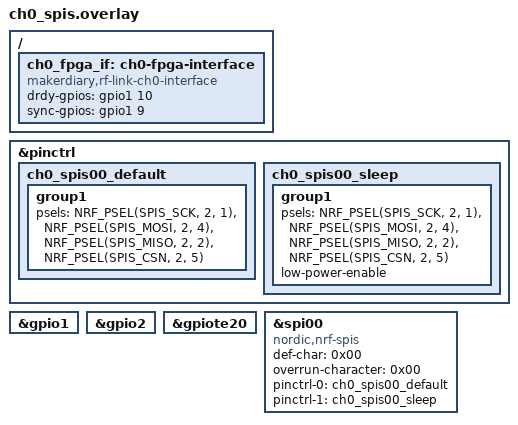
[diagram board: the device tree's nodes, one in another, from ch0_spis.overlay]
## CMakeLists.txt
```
#
# Copyright (c) 2018 Nordic Semiconductor
# Copyright (c) 2016-2025 Makerdiary <https://makerdiary.com>
#
# SPDX-License-Identifier: LicenseRef-Nordic-5-Clause
#
cmake_minimum_required(VERSION 3.20.0)

set(USER_CACHE_DIR "${CMAKE_BINARY_DIR}/zephyr_cache" CACHE PATH "Local build cache")
find_package(Zephyr REQUIRED HINTS $ENV{ZEPHYR_BASE})
project(rf_link_rx)

# NORDIC SDK APP START
target_sources(app PRIVATE
  src/main.c
  src/debug_uart.c
  src/radio_link.c
  src/rx_reorder.c
  src/rx_sample_stream.c
  src/timebase.c
)

target_sources_ifdef(CONFIG_RF_LINK_FUTURE_MODE app PRIVATE
  src/frame_queue.c
  src/sync_manager.c
  src/fpga_transport.c
  src/fpga_spi_transport.c
  src/link_control.c
)

target_sources_ifdef(CONFIG_RF_LINK_FPGA_SPIS app PRIVATE
  src/fpga_spis_backend.c
)

target_include_directories(app PRIVATE
  src
  ${CMAKE_CURRENT_SOURCE_DIR}/../rf_link_common
)

# NORDIC SDK APP END
```

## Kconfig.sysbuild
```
source "share/sysbuild/Kconfig"
```

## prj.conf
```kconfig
CONFIG_NCS_APPLICATION_BOOT_BANNER_STRING="RF Link RX"

CONFIG_SERIAL=y
CONFIG_CONSOLE=y
CONFIG_UART_CONSOLE=n

CONFIG_ESB=y
CONFIG_ESB_MAX_PAYLOAD_LENGTH=224
CONFIG_ESB_TX_FIFO_SIZE=16
CONFIG_ESB_RX_FIFO_SIZE=16
CONFIG_CLOCK_CONTROL=y
CONFIG_NRFX_DPPI10=y
CONFIG_ASSERT=y

CONFIG_MAIN_STACK_SIZE=4096
```

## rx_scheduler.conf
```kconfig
CONFIG_MAIN_THREAD_PRIORITY=1
CONFIG_RF_LINK_FPGA_SPIS_THREAD_PRIORITY=0
```

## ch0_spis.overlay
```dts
#include <zephyr/dt-bindings/gpio/gpio.h>
#include <zephyr/dt-bindings/pinctrl/nrf-pinctrl.h>

/ {
	ch0_fpga_if: ch0-fpga-interface {
		compatible = "makerdiary,rf-link-ch0-interface";
		drdy-gpios = <&gpio1 10 GPIO_ACTIVE_HIGH>;
		sync-gpios = <&gpio1 9 GPIO_ACTIVE_HIGH>;
	};
};

&pinctrl {
	ch0_spis00_default: ch0_spis00_default {
		group1 {
			psels = <NRF_PSEL(SPIS_SCK, 2, 1)>,
				<NRF_PSEL(SPIS_MOSI, 2, 4)>,
				<NRF_PSEL(SPIS_MISO, 2, 2)>,
				<NRF_PSEL(SPIS_CSN, 2, 5)>;
		};
	};

	ch0_spis00_sleep: ch0_spis00_sleep {
		group1 {
			psels = <NRF_PSEL(SPIS_SCK, 2, 1)>,
				<NRF_PSEL(SPIS_MOSI, 2, 4)>,
				<NRF_PSEL(SPIS_MISO, 2, 2)>,
				<NRF_PSEL(SPIS_CSN, 2, 5)>;
			low-power-enable;
		};
	};
};

&gpio1 {
	status = "okay";
};

&gpio2 {
	status = "okay";
};

&gpiote20 {
	status = "okay";
};

&spi00 {
	compatible = "nordic,nrf-spis";
	status = "okay";
	def-char = <0x00>;
	overrun-character = <0x00>;
	pinctrl-0 = <&ch0_spis00_default>;
	pinctrl-1 = <&ch0_spis00_sleep>;
	pinctrl-names = "default", "sleep";
	/delete-property/ rx-delay-supported;
	/delete-property/ rx-delay;
};
```

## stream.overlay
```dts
/*
 * Stream-only UART rate selection. Pin routing remains defined by the board
 * and the application's normal board overlay.
 */
&uart30 {
	current-speed = <1000000>;
};
```

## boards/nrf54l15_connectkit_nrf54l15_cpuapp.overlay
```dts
/ {
	chosen {
		zephyr,console = &uart30;
		zephyr,shell-uart = &uart30;
	};
};

&uart30 {
	status = "okay";
	current-speed = <115200>;
	/delete-property/ hw-flow-control;
};
```

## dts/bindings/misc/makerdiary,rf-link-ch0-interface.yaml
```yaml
description: CH0 FPGA sideband GPIOs for the RF Link receiver

compatible: "makerdiary,rf-link-ch0-interface"

properties:
  drdy-gpios:
    type: phandle-array
    required: true
    description: Active-high level indicating a pending PEEK record

  sync-gpios:
    type: phandle-array
    required: true
    description: Active-high external synchronization input
```

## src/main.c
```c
#include <stdint.h>
#include <string.h>
#include <zephyr/app_version.h>
#include <zephyr/kernel.h>

#include "debug_uart.h"
#include "rf_link_proto.h"
#include "radio_link.h"
#include "rx_reorder.h"
#include "rx_sample_stream.h"
#include "timebase.h"

#if defined(CONFIG_RF_LINK_FUTURE_MODE)
#include "fpga_transport.h"
#include "fpga_spis_backend.h"
#include "frame_queue.h"
#include "link_control.h"
#include "sync_manager.h"
#endif

static void print_boot_line(void)
{
	debug_uart_puts("\r\nrf_link_rx started");
	debug_uart_crlf();
	debug_uart_puts("mode=ESB_PRX,phy=");
	debug_uart_puts(radio_link_phy_label());
	debug_uart_puts(",ack=");
	debug_uart_puts(RF_LINK_NOACK_STREAM ? "noack" : "ack");
	debug_uart_puts(",channel=");
	debug_uart_u32(RF_LINK_CHANNEL);
	debug_uart_puts(",pipe=");
	debug_uart_u32(RF_LINK_PIPE);
	debug_uart_puts(",prefix=0x54,fw=");
	debug_uart_puts(STRINGIFY(APP_BUILD_VERSION));
	debug_uart_puts(",samples_per_frame=");
	debug_uart_u32(RF_LINK_FRAME_SAMPLE_COUNT);
#if defined(CONFIG_RF_LINK_FUTURE_MODE)
	debug_uart_puts(",v2_preview=1,node_id=");
	debug_uart_u32(CONFIG_RF_LINK_NODE_ID);
#endif
	debug_uart_crlf();
}

#if !defined(CONFIG_RF_LINK_FUTURE_MODE)
static void print_stats(uint32_t last_bytes, int64_t last_ms)
{
	struct radio_link_stats radio_stats;
	struct rx_reorder_stats rx_stats;
	uint32_t delta_bytes;
	uint32_t bps = 0;
	int64_t now = k_uptime_get();
	int64_t delta_ms = now - last_ms;

	radio_link_stats_get(&radio_stats);
	rx_reorder_stats_get(&rx_stats);

	delta_bytes = rx_stats.bytes - last_bytes;
	if (delta_ms > 0) {
		bps = (uint32_t)(((uint64_t)delta_bytes * 8000ull) / (uint64_t)delta_ms);
	}

	debug_uart_puts("RX stat frames=");
	debug_uart_u32(rx_stats.frames);
	debug_uart_puts(" samples=");
	debug_uart_u32(rx_stats.samples);
	debug_uart_puts(" bps=");
	debug_uart_u32(bps);
	debug_uart_puts(" lost=");
	debug_uart_u32(rx_stats.lost_frames);
	debug_uart_puts(" dup=");
	debug_uart_u32(rx_stats.duplicates);
	debug_uart_puts(" late=");
	debug_uart_u32(rx_stats.late_frames);
	debug_uart_puts(" bad=");
	debug_uart_u32(rx_stats.bad_magic + rx_stats.bad_size +
		       rx_stats.bad_sample_count);
	debug_uart_puts(" rf_evt=");
	debug_uart_u32(radio_stats.rx_events);
	debug_uart_puts(" rf_frames=");
	debug_uart_u32(radio_stats.rx_frames);
	debug_uart_puts(" rf_read_err=");
	debug_uart_u32(radio_stats.rx_read_errors);
	debug_uart_puts(" rf_q_ovf=");
	debug_uart_u32(radio_stats.rx_queue_overflow);
	debug_uart_puts(" rf_q_hwm=");
	debug_uart_u32(radio_stats.rx_queue_high_water);
	debug_uart_puts(" seq=");
	debug_uart_u32(rx_stats.last_seq);
	debug_uart_puts(" first=");
	debug_uart_i32(rx_stats.last_first_sample);
	debug_uart_puts(" last=");
	debug_uart_i32(rx_stats.last_last_sample);
	debug_uart_crlf();
}
#endif

#if defined(CONFIG_RF_LINK_FUTURE_MODE)
static void print_future_stats(void)
{
	struct frame_queue_stats queue_stats;
	struct link_control_status control_stats;
	struct radio_link_stats radio_stats;
	struct rx_reorder_stats reorder_stats;
	struct sync_status sync_stats;
	struct transport_stats transport_stats;

	radio_link_stats_get(&radio_stats);
	rx_reorder_stats_get(&reorder_stats);
	frame_queue_stats_get(&queue_stats);
	sync_manager_get_status(&sync_stats);
	memset(&transport_stats, 0, sizeof(transport_stats));
	if (IS_ENABLED(CONFIG_RF_LINK_FPGA_TRANSPORT)) {
		fpga_transport_get_stats(&transport_stats);
	}
	link_control_get_status(&control_stats);

	debug_uart_puts("RADIO events=");
	debug_uart_u32(radio_stats.rx_events);
	debug_uart_puts(" frames=");
	debug_uart_u32(radio_stats.rx_frames);
	debug_uart_puts(" read_errors=");
	debug_uart_u32(radio_stats.rx_read_errors);
	debug_uart_puts(" queue_overflow=");
	debug_uart_u32(radio_stats.rx_queue_overflow);
	debug_uart_puts(" queue_high_water=");
	debug_uart_u32(radio_stats.rx_queue_high_water);
	debug_uart_crlf();

	debug_uart_puts("REORDER extended_frame_seq=");
	debug_uart_u32(reorder_stats.extended_frame_seq);
	debug_uart_puts(" rf_lost_frames=");
	debug_uart_u32(reorder_stats.lost_frames);
	debug_uart_puts(" rf_lost_samples=");
	debug_uart_u32(reorder_stats.lost_samples);
	debug_uart_puts(" rf_duplicates=");
	debug_uart_u32(reorder_stats.duplicates);
	debug_uart_puts(" rf_late_frames=");
	debug_uart_u32(reorder_stats.late_frames);
	debug_uart_puts(" index_estimated=");
	debug_uart_u32(reorder_stats.index_estimated);
	debug_uart_puts(" bad_magic=");
	debug_uart_u32(reorder_stats.bad_magic);
	debug_uart_puts(" bad_size=");
	debug_uart_u32(reorder_stats.bad_size);
	debug_uart_puts(" bad_sample_count=");
	debug_uart_u32(reorder_stats.bad_sample_count);
	debug_uart_crlf();

	debug_uart_puts("SYNC state=");
	debug_uart_u32(sync_stats.state);
	debug_uart_puts(" sync_capture_count=");
	debug_uart_u32(sync_stats.sync_capture_count);
	debug_uart_puts(" sync_timeout=");
	debug_uart_u32(sync_stats.sync_timeout);
	debug_uart_puts(" sync_epoch=");
	debug_uart_u32(sync_stats.sync_epoch);
	debug_uart_puts(" sync_locked=");
	debug_uart_u32(sync_stats.sync_locked ? 1u : 0u);
	debug_uart_puts(" resync_count=");
	debug_uart_u32(sync_stats.resync_count);
	debug_uart_crlf();

	debug_uart_puts("QUEUE push_total=");
	debug_uart_u32(queue_stats.push_total);
	debug_uart_puts(" pop_total=");
	debug_uart_u32(queue_stats.pop_total);
	debug_uart_puts(" overflow=");
	debug_uart_u32(queue_stats.overflow);
	debug_uart_puts(" high_water=");
	debug_uart_u32(queue_stats.high_water);
	debug_uart_puts(" level=");
	debug_uart_u32(frame_queue_level());
	debug_uart_crlf();

	debug_uart_puts("SPI_TRANSPORT records=");
	debug_uart_u32(transport_stats.records);
	debug_uart_puts(" crc_errors=");
	debug_uart_u32(transport_stats.crc_errors);
	debug_uart_puts(" invalid_cmd=");
	debug_uart_u32(transport_stats.invalid_cmd);
	debug_uart_puts(" duplicate_commit=");
	debug_uart_u32(transport_stats.duplicate_commit);
	debug_uart_puts(" submit_errors=");
	debug_uart_u32(transport_stats.submit_errors);
	debug_uart_puts(" stall_ms=");
	debug_uart_u32(transport_stats.stall_ms);
	debug_uart_puts(" req_xfer=");
	debug_uart_u32(transport_stats.request_transactions);
	debug_uart_puts(" rsp_xfer=");
	debug_uart_u32(transport_stats.response_transactions);
	debug_uart_puts(" spi_errors=");
	debug_uart_u32(transport_stats.spi_errors);
	debug_uart_puts(" parser_errors=");
	debug_uart_u32(transport_stats.parser_errors);
	debug_uart_puts(" short_xfer=");
	debug_uart_u32(transport_stats.short_transfers);
	debug_uart_crlf();

#if defined(CONFIG_RF_LINK_FPGA_SPIS)
    struct fpga_spis_backend_stats physical;
    fpga_spis_backend_get_stats(&physical);
    debug_uart_puts("SPI_PHYSICAL req_len_err=");
    debug_uart_u32(physical.request_length_errors);
    debug_uart_puts(" rsp_len_err=");
    debug_uart_u32(physical.response_length_errors);
    debug_uart_puts(" recovery_discard=");
    debug_uart_u32(physical.recovery_discards);
    debug_uart_puts(" last_bad_req=");
    debug_uart_u32(physical.last_bad_request_length);
    debug_uart_puts(" last_bad_rsp=");
    debug_uart_u32(physical.last_bad_response_length);
    debug_uart_crlf();
#endif

	debug_uart_puts("CONTROL armed=");
	debug_uart_u32(control_stats.arm_commands);
	debug_uart_puts(" started=");
	debug_uart_u32(control_stats.start_commands);
	debug_uart_puts(" stopped=");
	debug_uart_u32(control_stats.stop_commands);
	debug_uart_puts(" reset=");
	debug_uart_u32(control_stats.reset_commands);
	debug_uart_puts(" invalid=");
	debug_uart_u32(control_stats.invalid_commands);
	debug_uart_crlf();
}

static int future_pipeline_init(void)
{
	int ret;

	frame_queue_init();
	link_control_init();
	ret = sync_manager_init();
	if (ret != 0) {
		return ret;
	}

	if (IS_ENABLED(CONFIG_RF_LINK_FPGA_TRANSPORT)) {
		return fpga_transport_init();
	}

	return 0;
}

static void future_process_record(struct rx_frame_record *record)
{
	struct rx_reorder_stats reorder_stats;
	int ret;

	if ((record->status_flags & RX_FRAME_STATUS_GAP_BEFORE) != 0u) {
		rx_reorder_stats_get(&reorder_stats);
		sync_manager_on_sequence_gap(
			reorder_stats.last_missing.frame_count);
	}

	sync_manager_on_frame(record);
	if (!link_control_streaming()) {
		return;
	}

	ret = frame_queue_push(record);
	if (ret != 0) {
		sync_manager_on_queue_overflow();
		return;
	}

	if (IS_ENABLED(CONFIG_RF_LINK_FPGA_TRANSPORT)) {
		(void)fpga_transport_service();
	} else {
		(void)frame_queue_commit(record->extended_frame_seq);
	}
}
#endif

int main(void)
{
#if !defined(CONFIG_RF_LINK_FUTURE_MODE)
	struct rx_reorder_stats rx_stats;
	uint32_t last_bytes = 0;
#endif
	struct radio_link_rx_packet packet;
	struct rx_frame_record record;
	int64_t last_ms;
	bool stream_mode = false;
	int ret;

	(void)debug_uart_init();
	print_boot_line();
	ret = timebase_init();
	if (ret != 0) {
		debug_uart_puts("timebase init failed err=");
		debug_uart_i32(ret);
		debug_uart_crlf();
		return ret;
	}

#if defined(CONFIG_RF_LINK_RX_SAMPLE_STREAM)
	if (debug_uart_ready()) {
		debug_uart_puts("rx_sample_stream enabled, switch host to baud=");
		debug_uart_u32(CONFIG_RF_LINK_RX_SAMPLE_STREAM_UART_BAUD);
		debug_uart_crlf();
	}
#endif

	if (IS_ENABLED(CONFIG_RF_LINK_RX_SAMPLE_STREAM)) {
		ret = rx_sample_stream_init();
		if (ret != 0) {
			if (debug_uart_ready()) {
				debug_uart_puts("rx_sample_stream init failed err=");
				debug_uart_i32(ret);
				debug_uart_crlf();
				debug_uart_puts("fall back to RX stat mode");
				debug_uart_crlf();
			}
		} else {
			stream_mode = true;
		}
	}

	rx_reorder_init();

#if defined(CONFIG_RF_LINK_FUTURE_MODE)
	ret = future_pipeline_init();
	if (ret != 0) {
		debug_uart_puts("future pipeline init failed err=");
		debug_uart_i32(ret);
		debug_uart_crlf();
		if (IS_ENABLED(CONFIG_RF_LINK_FPGA_SPIS)) {
			debug_uart_puts("CH0 SPIS backend init failed; check reviewed overlay and wiring");
			debug_uart_crlf();
		}
		return ret;
	}
#endif

	ret = radio_link_init();
	if (ret != 0) {
		if (!stream_mode) {
			debug_uart_puts("radio init failed err=");
			debug_uart_i32(ret);
			debug_uart_crlf();
		}
		return ret;
	}

	if (!stream_mode) {
		debug_uart_puts("radio ready, waiting packets");
		debug_uart_crlf();
	}

	last_ms = k_uptime_get();
	while (1) {
		ret = radio_link_receive(&packet, K_MSEC(20));
		if (ret == 0) {
			ret = rx_reorder_process_packet(&packet.frame, packet.length,
						 packet.rx_tick, &record);
			if (ret == 0) {
#if defined(CONFIG_RF_LINK_FUTURE_MODE)
				future_process_record(&record);
#else
				rx_sample_stream_submit_frame(&record.frame);
#endif
			}
		}

#if defined(CONFIG_RF_LINK_FUTURE_MODE)
		sync_manager_poll(timebase_now_ticks());
		if (IS_ENABLED(CONFIG_RF_LINK_FPGA_TRANSPORT)) {
			(void)fpga_transport_service();
		}
#endif

		if (!stream_mode &&
		    (k_uptime_get() - last_ms) >= RF_LINK_STATUS_PERIOD_MS) {
#if defined(CONFIG_RF_LINK_FUTURE_MODE)
			print_future_stats();
#else
			print_stats(last_bytes, last_ms);
			rx_reorder_stats_get(&rx_stats);
			last_bytes = rx_stats.bytes;
#endif
			last_ms = k_uptime_get();
		}
	}
}
```

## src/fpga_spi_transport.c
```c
#include "fpga_spi_transport.h"

#include <errno.h>
#include <stddef.h>
#include <string.h>
#include <zephyr/spinlock.h>
#include <zephyr/sys/crc.h>

static struct k_spinlock spi_lock;
static struct fpga_record pending_record;
static struct fpga_spi_transport_stats spi_stats;
static fpga_spi_release_cb_t release_callback;
static fpga_spi_control_cb_t control_callback;
static void *callback_context;
static uint32_t pending_extended_frame_seq;
static uint32_t last_committed_transport_seq;
static bool have_last_commit;
static bool have_pending_record;
static bool commit_in_progress;
static bool abort_requested;

static uint16_t record_header_crc(const struct fpga_record_header *header)
{
	return crc16(0x1021u, 0xffffu, (const uint8_t *)header,
		     offsetof(struct fpga_record_header, header_crc16));
}

static bool record_crc_valid(const struct fpga_record *record)
{
	return record != NULL &&
	       record->header.magic == FPGA_RECORD_MAGIC &&
	       record->header.version == FPGA_RECORD_VERSION &&
	       record->header.payload_len == RF_LINK_FRAME_WIRE_SIZE &&
	       record->header.header_crc16 == record_header_crc(&record->header) &&
	       record->payload_crc32 ==
		crc32_ieee((const uint8_t *)&record->frame, sizeof(record->frame));
}

int fpga_spi_transport_init(fpga_spi_release_cb_t release_cb,
			    fpga_spi_control_cb_t control_cb,
			    void *context)
{
	k_spinlock_key_t key;

	if (release_cb == NULL) {
		return -EINVAL;
	}

	key = k_spin_lock(&spi_lock);
	memset(&pending_record, 0, sizeof(pending_record));
	memset(&spi_stats, 0, sizeof(spi_stats));
	release_callback = release_cb;
	control_callback = control_cb;
	callback_context = context;
	pending_extended_frame_seq = 0u;
	last_committed_transport_seq = 0u;
	have_last_commit = false;
	have_pending_record = false;
	commit_in_progress = false;
	abort_requested = false;
	k_spin_unlock(&spi_lock, key);
	return 0;
}

int fpga_spi_transport_stage(const struct fpga_record *record,
			     uint32_t extended_frame_seq)
{
	k_spinlock_key_t key;

	if (!record_crc_valid(record)) {
		key = k_spin_lock(&spi_lock);
		spi_stats.crc_errors++;
		k_spin_unlock(&spi_lock, key);
		return -EBADMSG;
	}

	key = k_spin_lock(&spi_lock);
	if (have_pending_record) {
		k_spin_unlock(&spi_lock, key);
		return -EBUSY;
	}

	pending_record = *record;
	pending_extended_frame_seq = extended_frame_seq;
	have_pending_record = true;
	k_spin_unlock(&spi_lock, key);
	return 0;
}

static int commit_or_drop(uint32_t transport_seq, bool drop)
{
	uint32_t extended_frame_seq;
	int ret;
	k_spinlock_key_t key = k_spin_lock(&spi_lock);

	if (!have_pending_record) {
		if (have_last_commit && transport_seq == last_committed_transport_seq) {
			spi_stats.duplicate_commit++;
			k_spin_unlock(&spi_lock, key);
			return -EALREADY;
		}

		spi_stats.invalid_cmd++;
		k_spin_unlock(&spi_lock, key);
		return -ENODATA;
	}
	if (commit_in_progress) {
		k_spin_unlock(&spi_lock, key);
		return -EBUSY;
	}

	if (transport_seq != pending_record.header.transport_seq) {
		spi_stats.invalid_cmd++;
		k_spin_unlock(&spi_lock, key);
		return -ESTALE;
	}

	extended_frame_seq = pending_extended_frame_seq;
	commit_in_progress = true;
	k_spin_unlock(&spi_lock, key);
	ret = release_callback(extended_frame_seq, drop, callback_context);
	key = k_spin_lock(&spi_lock);
	commit_in_progress = false;
	if (abort_requested) {
		abort_requested = false;
		have_pending_record = false;
		k_spin_unlock(&spi_lock, key);
		return (ret == 0) ? -ECANCELED : ret;
	}
	if (ret != 0) {
		k_spin_unlock(&spi_lock, key);
		return ret;
	}

	last_committed_transport_seq = transport_seq;
	have_last_commit = true;
	have_pending_record = false;
	if (drop) {
		spi_stats.drop_total++;
	} else {
		spi_stats.commit_total++;
	}
	k_spin_unlock(&spi_lock, key);
	return 0;
}

int fpga_spi_transport_execute(const struct fpga_command *command,
			       struct fpga_response *response)
{
	int ret = 0;
	k_spinlock_key_t key;

	if (command == NULL || response == NULL) {
		return -EINVAL;
	}

	memset(response, 0, sizeof(*response));
	switch ((enum fpga_command_code)command->code) {
	case FPGA_CMD_GET_INFO:
	case FPGA_CMD_GET_STATUS:
		break;
	case FPGA_CMD_PEEK_RECORD:
	case FPGA_CMD_READ_RECORD:
		key = k_spin_lock(&spi_lock);
		if (!have_pending_record) {
			ret = -ENODATA;
		} else {
			response->record = pending_record;
			response->record_valid = true;
			response->transport_seq =
				pending_record.header.transport_seq;
			spi_stats.read_total++;
		}
		k_spin_unlock(&spi_lock, key);
		break;
	case FPGA_CMD_COMMIT_RECORD:
		ret = commit_or_drop(command->argument, false);
		break;
	case FPGA_CMD_DROP_RECORD:
		ret = commit_or_drop(command->argument, true);
		break;
	case FPGA_CMD_CLEAR_STATS:
		key = k_spin_lock(&spi_lock);
		memset(&spi_stats, 0, sizeof(spi_stats));
		k_spin_unlock(&spi_lock, key);
		if (control_callback != NULL) {
			ret = control_callback(FPGA_CMD_CLEAR_STATS, 0u,
					       callback_context);
		}
		break;
	case FPGA_CMD_ARM_SYNC:
	case FPGA_CMD_START_STREAM:
	case FPGA_CMD_STOP_STREAM:
	case FPGA_CMD_RESET_LINK:
		if (control_callback == NULL) {
			ret = -ENOTSUP;
		} else {
			ret = control_callback(
				(enum fpga_command_code)command->code,
				command->argument, callback_context);
		}
		break;
	default:
		key = k_spin_lock(&spi_lock);
		spi_stats.invalid_cmd++;
		k_spin_unlock(&spi_lock, key);
		ret = -ENOTSUP;
		break;
	}

	response->status = ret;
	return ret;
}

bool fpga_spi_transport_pending(void)
{
	k_spinlock_key_t key = k_spin_lock(&spi_lock);
	bool pending = have_pending_record;

	k_spin_unlock(&spi_lock, key);
	return pending;
}

uint32_t fpga_spi_transport_pending_seq(void)
{
	k_spinlock_key_t key = k_spin_lock(&spi_lock);
	uint32_t seq = have_pending_record ?
		pending_record.header.transport_seq : UINT32_MAX;

	k_spin_unlock(&spi_lock, key);
	return seq;
}

void fpga_spi_transport_abort_pending(void)
{
	k_spinlock_key_t key = k_spin_lock(&spi_lock);

	if (commit_in_progress) {
		abort_requested = true;
		k_spin_unlock(&spi_lock, key);
		return;
	}

	have_pending_record = false;
	pending_extended_frame_seq = 0u;
	commit_in_progress = false;
	abort_requested = false;
	k_spin_unlock(&spi_lock, key);
}

void fpga_spi_transport_stats_get(struct fpga_spi_transport_stats *stats)
{
	k_spinlock_key_t key;

	if (stats == NULL) {
		return;
	}

	key = k_spin_lock(&spi_lock);
	*stats = spi_stats;
	k_spin_unlock(&spi_lock, key);
}
```

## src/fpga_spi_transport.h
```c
#ifndef RF_LINK_FPGA_SPI_TRANSPORT_H_
#define RF_LINK_FPGA_SPI_TRANSPORT_H_

#include <stdbool.h>
#include <stdint.h>

#include "rf_link_future.h"

enum fpga_command_code {
	FPGA_CMD_GET_INFO = 1,
	FPGA_CMD_GET_STATUS,
	FPGA_CMD_PEEK_RECORD,
	FPGA_CMD_READ_RECORD,
	FPGA_CMD_COMMIT_RECORD,
	FPGA_CMD_DROP_RECORD,
	FPGA_CMD_CLEAR_STATS,
	FPGA_CMD_ARM_SYNC,
	FPGA_CMD_START_STREAM,
	FPGA_CMD_STOP_STREAM,
	FPGA_CMD_RESET_LINK,
};

#define FPGA_INFO_MAGIC                 0x3149464eu
#define FPGA_STATUS_MAGIC               0x3153464eu
#define FPGA_SPI_CONTRACT_VERSION       1u
#define FPGA_SPI_BIT_ORDER_MSB_FIRST    0u
#define FPGA_CAP_PEEK_COMMIT            BIT(0)
#define FPGA_CAP_LEVEL_DRDY             BIT(1)
#define FPGA_CAP_HW_SYNC_CAPTURE        BIT(2)

struct fpga_info_payload {
	uint32_t magic;
	uint16_t contract_version;
	uint16_t capabilities;
	uint16_t request_size;
	uint16_t response_size;
	uint16_t record_size;
	uint8_t spi_mode;
	uint8_t bit_order;
	uint32_t max_sclk_hz;
	uint32_t initial_sclk_hz;
	uint32_t min_request_response_gap_us;
} __packed;

struct fpga_status_payload {
	uint32_t magic;
	uint16_t contract_version;
	uint16_t sync_state;
	uint32_t queue_level;
	uint32_t queue_high_water;
	uint32_t sync_epoch;
	uint64_t sync_tick;
	uint32_t pending_transport_seq;
	uint32_t crc_errors;
	uint32_t invalid_cmd;
	uint32_t duplicate_commit;
	uint32_t spi_errors;
	uint32_t parser_errors;
	uint32_t short_transfers;
} __packed;

struct fpga_command {
	uint8_t code;
	uint8_t reserved[3];
	uint32_t argument;
} __packed;

struct fpga_response {
	int32_t status;
	uint32_t transport_seq;
	uint8_t record_valid;
	uint8_t reserved[3];
	union {
		struct fpga_record record;
		uint8_t payload[sizeof(struct fpga_record)];
	};
} __packed;

/*
 * The command engine's current wire image is little-endian on nRF54L15.
 * A physical SPIS backend may add turnaround/dummy clocks, but it must not
 * silently change these request/response payload sizes.
 */
#define FPGA_SPI_REQUEST_SIZE  8u
#define FPGA_SPI_RESPONSE_SIZE 260u

BUILD_ASSERT(sizeof(struct fpga_command) == FPGA_SPI_REQUEST_SIZE,
	     "fpga_command wire size changed");
BUILD_ASSERT(sizeof(struct fpga_response) == FPGA_SPI_RESPONSE_SIZE,
	     "fpga_response wire size changed");
BUILD_ASSERT(sizeof(struct fpga_info_payload) == 28u,
	     "GET_INFO wire payload size changed");
BUILD_ASSERT(sizeof(struct fpga_status_payload) == 56u,
	     "GET_STATUS wire payload size changed");
BUILD_ASSERT(sizeof(struct fpga_status_payload) <= sizeof(struct fpga_record),
	     "status payload is too large for the response envelope");

struct fpga_spi_transport_stats {
	uint32_t crc_errors;
	uint32_t invalid_cmd;
	uint32_t duplicate_commit;
	uint32_t read_total;
	uint32_t commit_total;
	uint32_t drop_total;
};

typedef int (*fpga_spi_release_cb_t)(uint32_t extended_frame_seq,
				      bool drop, void *context);
typedef int (*fpga_spi_control_cb_t)(enum fpga_command_code command,
				      uint32_t argument, void *context);

int fpga_spi_transport_init(fpga_spi_release_cb_t release_cb,
			    fpga_spi_control_cb_t control_cb,
			    void *context);
int fpga_spi_transport_stage(const struct fpga_record *record,
			     uint32_t extended_frame_seq);
int fpga_spi_transport_execute(const struct fpga_command *command,
			       struct fpga_response *response);
bool fpga_spi_transport_pending(void);
uint32_t fpga_spi_transport_pending_seq(void);
void fpga_spi_transport_abort_pending(void);
void fpga_spi_transport_stats_get(struct fpga_spi_transport_stats *stats);

#endif /* RF_LINK_FPGA_SPI_TRANSPORT_H_ */
```

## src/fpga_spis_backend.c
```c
#include "fpga_spis_backend.h"

#include <errno.h>
#include <string.h>
#include <zephyr/device.h>
#include <zephyr/devicetree.h>
#include <zephyr/drivers/gpio.h>
#include <zephyr/drivers/spi.h>
#include <zephyr/kernel.h>
#include <zephyr/spinlock.h>
#include <zephyr/sys/util.h>

#include "fpga_spi_transport.h"
#include "fpga_transport.h"
#include "frame_queue.h"
#include "sync_manager.h"

#define CH0_SPIS_NODE DT_NODELABEL(spi00)
#define CH0_FPGA_IF_NODE DT_NODELABEL(ch0_fpga_if)

BUILD_ASSERT(DT_NODE_HAS_STATUS(CH0_SPIS_NODE, okay),
	     "CH0 overlay must enable spi00");
BUILD_ASSERT(DT_NODE_HAS_PROP(CH0_FPGA_IF_NODE, drdy_gpios),
	     "CH0 overlay must define drdy-gpios");

static const struct device *const spis = DEVICE_DT_GET(CH0_SPIS_NODE);
static const struct gpio_dt_spec drdy =
	GPIO_DT_SPEC_GET(CH0_FPGA_IF_NODE, drdy_gpios);
static const struct spi_config spis_config = {
	.frequency = 1000000u,
	.operation = SPI_OP_MODE_SLAVE | SPI_WORD_SET(8),
	.slave = 0u,
};

static uint8_t request_tx[FPGA_SPI_REQUEST_SIZE];
/* RX AMOUNT is capped by MAXCNT. A full recovery transaction must
 * remain distinguishable from an eight-byte command, even if the master
 * and slave have lost their A/B phase agreement. */
static uint8_t request_rx[FPGA_SPI_RESPONSE_SIZE];
static uint8_t response_rx[FPGA_SPI_RESPONSE_SIZE];
static struct fpga_response response_tx;
static struct k_thread spis_thread;
K_THREAD_STACK_DEFINE(spis_stack,
		      CONFIG_RF_LINK_FPGA_SPIS_THREAD_STACK_SIZE);
static struct k_spinlock backend_lock;
static struct fpga_spis_backend_stats backend_stats;
static bool backend_ready;

static void backend_stat_inc(uint32_t *counter)
{
	k_spinlock_key_t key = k_spin_lock(&backend_lock);

	(*counter)++;
	k_spin_unlock(&backend_lock, key);
}

static void update_drdy(void)
{
	(void)gpio_pin_set_dt(&drdy, fpga_spi_transport_pending() ? 1 : 0);
}

static void fill_info_response(struct fpga_response *response)
{
	struct fpga_info_payload info = {
		.magic = FPGA_INFO_MAGIC,
		.contract_version = FPGA_SPI_CONTRACT_VERSION,
		.capabilities = FPGA_CAP_PEEK_COMMIT | FPGA_CAP_LEVEL_DRDY |
				FPGA_CAP_HW_SYNC_CAPTURE,
		.request_size = FPGA_SPI_REQUEST_SIZE,
		.response_size = FPGA_SPI_RESPONSE_SIZE,
		.record_size = sizeof(struct fpga_record),
		.spi_mode = 0u,
		.bit_order = FPGA_SPI_BIT_ORDER_MSB_FIRST,
		.max_sclk_hz = 8000000u,
		.initial_sclk_hz = 1000000u,
		.min_request_response_gap_us = 1000u,
	};

	memcpy(response->payload, &info, sizeof(info));
}

static void fill_status_response(struct fpga_response *response)
{
	struct fpga_status_payload status = {0};
	struct fpga_spi_transport_stats command_stats;
	struct fpga_spis_backend_stats physical_stats;
	struct frame_queue_stats queue_stats;
	struct sync_status sync_status;

	fpga_spi_transport_stats_get(&command_stats);
	fpga_spis_backend_get_stats(&physical_stats);
	frame_queue_stats_get(&queue_stats);
	sync_manager_get_status(&sync_status);
	status.magic = FPGA_STATUS_MAGIC;
	status.contract_version = FPGA_SPI_CONTRACT_VERSION;
	status.sync_state = (uint16_t)sync_status.state;
	status.queue_level = frame_queue_level();
	status.queue_high_water = queue_stats.high_water;
	status.sync_epoch = sync_status.sync_epoch;
	status.sync_tick = sync_status.sync_tick;
	status.pending_transport_seq = fpga_spi_transport_pending_seq();
	status.crc_errors = command_stats.crc_errors;
	status.invalid_cmd = command_stats.invalid_cmd;
	status.duplicate_commit = command_stats.duplicate_commit;
	status.spi_errors = physical_stats.spi_errors;
	status.parser_errors = physical_stats.parser_errors;
	status.short_transfers = physical_stats.short_transfers;
	memcpy(response->payload, &status, sizeof(status));
}

static bool request_reserved_valid(const struct fpga_command *command)
{
	return command->reserved[0] == 0u && command->reserved[1] == 0u &&
	       command->reserved[2] == 0u;
}

static void spis_worker(void *arg1, void *arg2, void *arg3)
{
	const struct spi_buf request_tx_buf = {
		.buf = request_tx,
		.len = sizeof(request_tx),
	};
	const struct spi_buf request_rx_buf = {
		.buf = request_rx,
		.len = sizeof(request_rx),
	};
	const struct spi_buf_set request_tx_set = {
		.buffers = &request_tx_buf,
		.count = 1u,
	};
	const struct spi_buf_set request_rx_set = {
		.buffers = &request_rx_buf,
		.count = 1u,
	};
	const struct spi_buf response_tx_buf = {
		.buf = &response_tx,
		.len = sizeof(response_tx),
	};
	const struct spi_buf response_rx_buf = {
		.buf = response_rx,
		.len = sizeof(response_rx),
	};
	const struct spi_buf_set response_tx_set = {
		.buffers = &response_tx_buf,
		.count = 1u,
	};
	const struct spi_buf_set response_rx_set = {
		.buffers = &response_rx_buf,
		.count = 1u,
	};
	struct fpga_command command;
	int ret;

	ARG_UNUSED(arg1);
	ARG_UNUSED(arg2);
	ARG_UNUSED(arg3);
	while (true) {
		memset(request_rx, 0, sizeof(request_rx));
		ret = spi_transceive(spis, &spis_config, &request_tx_set,
				     &request_rx_set);
		if (ret < 0) {
			backend_stat_inc(&backend_stats.spi_errors);
			continue;
		}
		backend_stat_inc(&backend_stats.request_transactions);
		if (ret != FPGA_SPI_REQUEST_SIZE) {
			backend_stat_inc(&backend_stats.short_transfers);
            backend_stat_inc(&backend_stats.request_length_errors);
            if (ret == FPGA_SPI_RESPONSE_SIZE) {
                backend_stat_inc(&backend_stats.recovery_discards);
            }
            backend_stats.last_bad_request_length = ret;
			continue;
		}

		memcpy(&command, request_rx, sizeof(command));
		memset(&response_tx, 0, sizeof(response_tx));
		if (!request_reserved_valid(&command)) {
			backend_stat_inc(&backend_stats.parser_errors);
			response_tx.status = -EBADMSG;
		} else {
			ret = fpga_spi_transport_execute(&command, &response_tx);
			if ((command.code == FPGA_CMD_COMMIT_RECORD ||
			     command.code == FPGA_CMD_DROP_RECORD) && ret == 0) {
				(void)fpga_transport_service();
			}
			if (command.code == FPGA_CMD_GET_INFO && ret == 0) {
				fill_info_response(&response_tx);
			} else if (command.code == FPGA_CMD_GET_STATUS && ret == 0) {
				fill_status_response(&response_tx);
			}
		}
		update_drdy();

		memset(response_rx, 0, sizeof(response_rx));
		ret = spi_transceive(spis, &spis_config, &response_tx_set,
				     &response_rx_set);
		if (ret < 0) {
			backend_stat_inc(&backend_stats.spi_errors);
			continue;
		}
		backend_stat_inc(&backend_stats.response_transactions);
		if (ret != FPGA_SPI_RESPONSE_SIZE) {
			backend_stat_inc(&backend_stats.short_transfers);
            backend_stat_inc(&backend_stats.response_length_errors);
            backend_stats.last_bad_response_length = ret;
		}
	}
}

int fpga_spis_backend_init(void)
{
	int ret;

	if (!device_is_ready(spis) || !gpio_is_ready_dt(&drdy)) {
		return -ENODEV;
	}
	memset(&backend_stats, 0, sizeof(backend_stats));
	ret = gpio_pin_configure_dt(&drdy, GPIO_OUTPUT_INACTIVE);
	if (ret != 0) {
		return ret;
	}
	backend_ready = true;
	k_thread_create(&spis_thread, spis_stack, K_THREAD_STACK_SIZEOF(spis_stack),
			spis_worker, NULL, NULL, NULL,
			CONFIG_RF_LINK_FPGA_SPIS_THREAD_PRIORITY, 0, K_NO_WAIT);
	k_thread_name_set(&spis_thread, "ch0_spis");
	return 0;
}

bool fpga_spis_backend_ready(void)
{
	return backend_ready;
}

int fpga_spis_backend_submit(const struct fpga_record *record,
			     uint32_t extended_frame_seq)
{
	int ret = fpga_spi_transport_stage(record, extended_frame_seq);

	if (ret == 0) {
		update_drdy();
	}
	return ret;
}

void fpga_spis_backend_get_stats(struct fpga_spis_backend_stats *stats)
{
	k_spinlock_key_t key;

	if (stats == NULL) {
		return;
	}
	key = k_spin_lock(&backend_lock);
	*stats = backend_stats;
	k_spin_unlock(&backend_lock, key);
}
```

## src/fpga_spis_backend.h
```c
#ifndef RF_LINK_FPGA_SPIS_BACKEND_H_
#define RF_LINK_FPGA_SPIS_BACKEND_H_

#include <stdbool.h>
#include <stdint.h>

#include "rf_link_future.h"

struct fpga_spis_backend_stats {
	uint32_t request_transactions;
	uint32_t response_transactions;
	uint32_t spi_errors;
	uint32_t parser_errors;
	uint32_t short_transfers;
    uint32_t request_length_errors;
    uint32_t response_length_errors;
    uint32_t recovery_discards;
    uint32_t last_bad_request_length;
    uint32_t last_bad_response_length;
};

int fpga_spis_backend_init(void);
bool fpga_spis_backend_ready(void);
int fpga_spis_backend_submit(const struct fpga_record *record,
			     uint32_t extended_frame_seq);
void fpga_spis_backend_get_stats(struct fpga_spis_backend_stats *stats);

#endif /* RF_LINK_FPGA_SPIS_BACKEND_H_ */
```

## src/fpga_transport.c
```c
#include "fpga_transport.h"

#include <errno.h>
#include <stddef.h>
#include <string.h>
#include <zephyr/kernel.h>
#include <zephyr/spinlock.h>
#include <zephyr/sys/crc.h>

#include "frame_queue.h"
#include "link_control.h"
#include "timebase.h"

#if defined(CONFIG_RF_LINK_FPGA_SPIS) && CONFIG_RF_LINK_FPGA_SPIS
#include "fpga_spis_backend.h"
#endif

static struct k_spinlock transport_lock;
K_MUTEX_DEFINE(transport_service_mutex);
static struct transport_stats transport_stats_data;
static uint32_t next_transport_seq;
static uint32_t pending_extended_frame_seq;
static uint64_t pending_since_tick;
static bool transport_initialized;

static uint16_t header_crc(const struct fpga_record_header *header)
{
	return crc16(0x1021u, 0xffffu, (const uint8_t *)header,
		     offsetof(struct fpga_record_header, header_crc16));
}

int fpga_transport_build_record(const struct rx_frame_record *source,
				uint32_t transport_seq,
				struct fpga_record *record)
{
	if (source == NULL || record == NULL) {
		return -EINVAL;
	}

	memset(record, 0, sizeof(*record));
	record->header.magic = FPGA_RECORD_MAGIC;
	record->header.version = FPGA_RECORD_VERSION;
	record->header.node_id = source->node_id;
	record->header.record_type = 1u;
	record->header.transport_seq = transport_seq;
	record->header.sync_epoch = source->sync_epoch;
	record->header.rx_tick = source->rx_tick;
	record->header.logical_sample_index = source->logical_sample_index;
	record->header.status_flags = source->status_flags;
	record->header.payload_len = RF_LINK_FRAME_WIRE_SIZE;
	record->header.header_crc16 = header_crc(&record->header);
	record->frame = source->frame;
	record->payload_crc32 =
		crc32_ieee((const uint8_t *)&record->frame, sizeof(record->frame));
	return 0;
}

bool fpga_transport_record_valid(const struct fpga_record *record)
{
	return record != NULL &&
	       record->header.magic == FPGA_RECORD_MAGIC &&
	       record->header.version == FPGA_RECORD_VERSION &&
	       record->header.payload_len == RF_LINK_FRAME_WIRE_SIZE &&
	       record->header.header_crc16 == header_crc(&record->header) &&
	       record->payload_crc32 ==
		crc32_ieee((const uint8_t *)&record->frame, sizeof(record->frame));
}

static int release_record(uint32_t extended_frame_seq, bool drop, void *context)
{
	int ret;

	ARG_UNUSED(drop);
	ARG_UNUSED(context);
	ret = frame_queue_commit(extended_frame_seq);
	if (ret == 0) {
		k_spinlock_key_t key = k_spin_lock(&transport_lock);

		next_transport_seq++;
		pending_since_tick = 0u;
		k_spin_unlock(&transport_lock, key);
	}
	return ret;
}

static int transport_control_command(enum fpga_command_code command,
				     uint32_t argument, void *context)
{
	k_spinlock_key_t key;

	if (command == FPGA_CMD_ARM_SYNC || command == FPGA_CMD_RESET_LINK) {
		fpga_spi_transport_abort_pending();
		key = k_spin_lock(&transport_lock);
		pending_since_tick = 0u;
		k_spin_unlock(&transport_lock, key);
	}

	if (command == FPGA_CMD_CLEAR_STATS) {
		key = k_spin_lock(&transport_lock);
		memset(&transport_stats_data, 0, sizeof(transport_stats_data));
		k_spin_unlock(&transport_lock, key);
	}

	return link_control_handle_command(command, argument, context);
}

static int debug_backend_init(void)
{
	return 0;
}

static bool debug_backend_ready(void)
{
	return true;
}

static int debug_backend_submit(const struct fpga_record *record)
{
	return fpga_transport_record_valid(record) ? 0 : -EBADMSG;
}

static int debug_backend_get_command(struct fpga_command *command)
{
	ARG_UNUSED(command);
	return -EAGAIN;
}

static void debug_backend_get_stats(struct transport_stats *stats)
{
	ARG_UNUSED(stats);
}

static const struct fpga_transport_api debug_backend = {
	.init = debug_backend_init,
	.ready = debug_backend_ready,
	.submit = debug_backend_submit,
	.get_command = debug_backend_get_command,
	.get_stats = debug_backend_get_stats,
};

static int spis_backend_init(void)
{
#if defined(CONFIG_RF_LINK_FPGA_SPIS) && CONFIG_RF_LINK_FPGA_SPIS
	return fpga_spis_backend_init();
#else
	return -ENOTSUP;
#endif
}

static bool spis_backend_ready(void)
{
#if defined(CONFIG_RF_LINK_FPGA_SPIS) && CONFIG_RF_LINK_FPGA_SPIS
	return fpga_spis_backend_ready();
#else
	return false;
#endif
}

static int spis_backend_submit(const struct fpga_record *record)
{
#if defined(CONFIG_RF_LINK_FPGA_SPIS) && CONFIG_RF_LINK_FPGA_SPIS
	return fpga_spis_backend_submit(record, pending_extended_frame_seq);
#else
	return fpga_spi_transport_stage(record, pending_extended_frame_seq);
#endif
}

static int spis_backend_get_command(struct fpga_command *command)
{
	ARG_UNUSED(command);
	return -EAGAIN;
}

static void spis_backend_get_stats(struct transport_stats *stats)
{
	struct fpga_spi_transport_stats spi_stats;
#if defined(CONFIG_RF_LINK_FPGA_SPIS) && CONFIG_RF_LINK_FPGA_SPIS
	struct fpga_spis_backend_stats physical_stats;
#endif

	if (stats == NULL) {
		return;
	}

	fpga_spi_transport_stats_get(&spi_stats);
	stats->crc_errors += spi_stats.crc_errors;
	stats->invalid_cmd += spi_stats.invalid_cmd;
	stats->duplicate_commit += spi_stats.duplicate_commit;
#if defined(CONFIG_RF_LINK_FPGA_SPIS) && CONFIG_RF_LINK_FPGA_SPIS
	fpga_spis_backend_get_stats(&physical_stats);
	stats->request_transactions += physical_stats.request_transactions;
	stats->response_transactions += physical_stats.response_transactions;
	stats->spi_errors += physical_stats.spi_errors;
	stats->parser_errors += physical_stats.parser_errors;
	stats->short_transfers += physical_stats.short_transfers;
#endif
}

static const struct fpga_transport_api spis_backend = {
	.init = spis_backend_init,
	.ready = spis_backend_ready,
	.submit = spis_backend_submit,
	.get_command = spis_backend_get_command,
	.get_stats = spis_backend_get_stats,
};

static const struct fpga_transport_api *selected_backend(void)
{
	if (IS_ENABLED(CONFIG_RF_LINK_FPGA_SPIS)) {
		return &spis_backend;
	}

	return &debug_backend;
}

int fpga_transport_init(void)
{
	const struct fpga_transport_api *backend = selected_backend();
	int ret;

	memset(&transport_stats_data, 0, sizeof(transport_stats_data));
	next_transport_seq = 0u;
	pending_extended_frame_seq = 0u;
	pending_since_tick = 0u;
	transport_initialized = false;

	ret = fpga_spi_transport_init(release_record,
				      transport_control_command, NULL);
	if (ret != 0) {
		return ret;
	}

	ret = backend->init();
	if (ret != 0) {
		return ret;
	}

	transport_initialized = true;
	return 0;
}

int fpga_transport_service(void)
{
	const struct fpga_transport_api *backend = selected_backend();
	struct rx_frame_record source;
	struct fpga_record record;
	int processed = 0;
	int result;
	int ret;

	ret = k_mutex_lock(&transport_service_mutex, K_FOREVER);
	if (ret != 0) {
		return ret;
	}

	if (!transport_initialized || !backend->ready()) {
		result = -EAGAIN;
		goto out_unlock;
	}

	while (true) {
		/* A pending record may be committed by the SPI worker without
		 * taking service_mutex. Check it before copying the queue head:
		 * otherwise the copy can refer to a head popped between peek and
		 * pending(), and become an uncommittable stale pending record.
		 * When pending is false, service_mutex excludes another stager. */
		if (IS_ENABLED(CONFIG_RF_LINK_FPGA_SPIS) &&
		    fpga_spi_transport_pending()) {
			break;
		}
		if (frame_queue_peek(&source) != 0) {
			break;
		}

		pending_extended_frame_seq = source.extended_frame_seq;
		ret = fpga_transport_build_record(&source, next_transport_seq,
						  &record);
		if (ret != 0) {
			result = ret;
			goto out_unlock;
		}

		ret = backend->submit(&record);
		if (ret != 0) {
			k_spinlock_key_t key = k_spin_lock(&transport_lock);

			transport_stats_data.submit_errors++;
			if (ret == -EBADMSG) {
				transport_stats_data.crc_errors++;
			}
			k_spin_unlock(&transport_lock, key);
			result = ret;
			goto out_unlock;
		}

		{
			k_spinlock_key_t key = k_spin_lock(&transport_lock);

			transport_stats_data.records++;
			if (pending_since_tick == 0u) {
				pending_since_tick = timebase_now_ticks();
			}
			k_spin_unlock(&transport_lock, key);
		}
		processed++;

		if (IS_ENABLED(CONFIG_RF_LINK_FPGA_SPIS)) {
			break;
		}

		ret = release_record(source.extended_frame_seq, false, NULL);
		if (ret != 0) {
			result = ret;
			goto out_unlock;
		}
	}

	result = processed;

out_unlock:
	k_mutex_unlock(&transport_service_mutex);
	return result;
}

void fpga_transport_get_stats(struct transport_stats *stats)
{
	const struct fpga_transport_api *backend = selected_backend();
	uint64_t elapsed_ticks;
	uint32_t frequency;
	k_spinlock_key_t key;

	if (stats == NULL) {
		return;
	}

	key = k_spin_lock(&transport_lock);
	*stats = transport_stats_data;
	if (pending_since_tick != 0u) {
		elapsed_ticks = timebase_now_ticks() - pending_since_tick;
		frequency = timebase_frequency_hz();
		if (frequency != 0u) {
			stats->stall_ms = (uint32_t)MIN(
				(elapsed_ticks * 1000u) / frequency, UINT32_MAX);
		}
	}
	k_spin_unlock(&transport_lock, key);
	backend->get_stats(stats);
}
```

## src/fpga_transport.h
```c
#ifndef RF_LINK_FPGA_TRANSPORT_H_
#define RF_LINK_FPGA_TRANSPORT_H_

#include <stdbool.h>
#include <stdint.h>

#include "fpga_spi_transport.h"
#include "rf_link_future.h"

struct transport_stats {
	uint32_t records;
	uint32_t crc_errors;
	uint32_t invalid_cmd;
	uint32_t duplicate_commit;
	uint32_t submit_errors;
	uint32_t stall_ms;
	uint32_t request_transactions;
	uint32_t response_transactions;
	uint32_t spi_errors;
	uint32_t parser_errors;
	uint32_t short_transfers;
};

struct fpga_transport_api {
	int (*init)(void);
	bool (*ready)(void);
	int (*submit)(const struct fpga_record *record);
	int (*get_command)(struct fpga_command *command);
	void (*get_stats)(struct transport_stats *stats);
};

int fpga_transport_init(void);
int fpga_transport_service(void);
int fpga_transport_build_record(const struct rx_frame_record *source,
				uint32_t transport_seq,
				struct fpga_record *record);
bool fpga_transport_record_valid(const struct fpga_record *record);
void fpga_transport_get_stats(struct transport_stats *stats);

#endif /* RF_LINK_FPGA_TRANSPORT_H_ */
```

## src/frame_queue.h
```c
#ifndef RF_LINK_FRAME_QUEUE_H_
#define RF_LINK_FRAME_QUEUE_H_

#include <stddef.h>
#include <stdint.h>

#include "rf_link_future.h"

struct frame_queue_stats {
	uint32_t push_total;
	uint32_t pop_total;
	uint32_t overflow;
	uint32_t high_water;
};

void frame_queue_init(void);
int frame_queue_push(const struct rx_frame_record *record);
int frame_queue_peek(struct rx_frame_record *record);
int frame_queue_commit(uint32_t expected_extended_frame_seq);
void frame_queue_clear(void);
size_t frame_queue_level(void);
size_t frame_queue_high_water(void);
void frame_queue_stats_get(struct frame_queue_stats *stats);

#endif /* RF_LINK_FRAME_QUEUE_H_ */
```

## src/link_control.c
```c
#include "link_control.h"

#include <errno.h>
#include <string.h>
#include <zephyr/spinlock.h>

#include "frame_queue.h"
#include "sync_manager.h"

static struct k_spinlock control_lock;
static struct link_control_status control_status;

void link_control_init(void)
{
	k_spinlock_key_t key = k_spin_lock(&control_lock);

	memset(&control_status, 0, sizeof(control_status));
	control_status.streaming =
		IS_ENABLED(CONFIG_RF_LINK_DEBUG_UART_TRANSPORT);
	k_spin_unlock(&control_lock, key);
}

int link_control_handle_command(enum fpga_command_code command,
				uint32_t argument, void *context)
{
	int ret = 0;
	k_spinlock_key_t key;

	ARG_UNUSED(context);
	switch (command) {
	case FPGA_CMD_ARM_SYNC:
		frame_queue_clear();
		ret = sync_manager_arm(argument);
		key = k_spin_lock(&control_lock);
		control_status.arm_commands++;
		control_status.streaming = false;
		k_spin_unlock(&control_lock, key);
		break;
	case FPGA_CMD_START_STREAM:
		key = k_spin_lock(&control_lock);
		control_status.start_commands++;
		control_status.streaming = true;
		k_spin_unlock(&control_lock, key);
		break;
	case FPGA_CMD_STOP_STREAM:
		key = k_spin_lock(&control_lock);
		control_status.stop_commands++;
		control_status.streaming = false;
		k_spin_unlock(&control_lock, key);
		break;
	case FPGA_CMD_RESET_LINK:
		frame_queue_clear();
		sync_manager_stop();
		key = k_spin_lock(&control_lock);
		control_status.reset_commands++;
		control_status.streaming = false;
		k_spin_unlock(&control_lock, key);
		break;
	case FPGA_CMD_CLEAR_STATS:
		break;
	default:
		key = k_spin_lock(&control_lock);
		control_status.invalid_commands++;
		k_spin_unlock(&control_lock, key);
		ret = -ENOTSUP;
		break;
	}

	return ret;
}

bool link_control_streaming(void)
{
	k_spinlock_key_t key = k_spin_lock(&control_lock);
	bool streaming = control_status.streaming;

	k_spin_unlock(&control_lock, key);
	return streaming;
}

void link_control_get_status(struct link_control_status *status)
{
	k_spinlock_key_t key;

	if (status == NULL) {
		return;
	}

	key = k_spin_lock(&control_lock);
	*status = control_status;
	k_spin_unlock(&control_lock, key);
}
```

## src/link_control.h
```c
#ifndef RF_LINK_LINK_CONTROL_H_
#define RF_LINK_LINK_CONTROL_H_

#include <stdbool.h>
#include <stdint.h>

#include "fpga_spi_transport.h"

struct link_control_status {
	bool streaming;
	uint32_t arm_commands;
	uint32_t start_commands;
	uint32_t stop_commands;
	uint32_t reset_commands;
	uint32_t invalid_commands;
};

void link_control_init(void);
int link_control_handle_command(enum fpga_command_code command,
				uint32_t argument, void *context);
void link_control_get_status(struct link_control_status *status);
bool link_control_streaming(void);

#endif /* RF_LINK_LINK_CONTROL_H_ */
```

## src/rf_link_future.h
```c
#ifndef RF_LINK_FUTURE_H_
#define RF_LINK_FUTURE_H_

#include <stdint.h>
#include <zephyr/sys/util.h>

#include "rf_link_proto.h"

#define RF_LINK_PROTOCOL_VERSION_V1 1u
#define FPGA_RECORD_MAGIC            0x3146524eu
#define FPGA_RECORD_VERSION          1u

#define RX_FRAME_STATUS_VALID            BIT(0)
#define RX_FRAME_STATUS_GAP_BEFORE       BIT(1)
#define RX_FRAME_STATUS_INDEX_ESTIMATED  BIT(2)
#define RX_FRAME_STATUS_BATCH_START      BIT(3)
#define RX_FRAME_STATUS_BATCH_END        BIT(4)
#define RX_FRAME_STATUS_SYNCED           BIT(5)
#define RX_FRAME_STATUS_SYNC_DEGRADED    BIT(6)

struct rx_missing_range {
	uint32_t first_extended_frame_seq;
	uint32_t frame_count;
	uint64_t first_logical_sample_index;
	uint64_t estimated_sample_count;
};

struct rx_frame_record {
	uint8_t node_id;
	uint8_t protocol_version;
	uint16_t reserved;
	uint32_t extended_frame_seq;
	uint32_t sync_epoch;
	uint64_t rx_tick;
	uint64_t logical_sample_index;
	uint32_t status_flags;
	struct rf_frame frame;
};

struct fpga_record_header {
	uint32_t magic;
	uint8_t version;
	uint8_t node_id;
	uint16_t record_type;
	uint32_t transport_seq;
	uint32_t sync_epoch;
	uint64_t rx_tick;
	uint64_t logical_sample_index;
	uint32_t status_flags;
	uint16_t payload_len;
	uint16_t header_crc16;
} __packed;

struct fpga_record {
	struct fpga_record_header header;
	struct rf_frame frame;
	uint32_t payload_crc32;
} __packed;

BUILD_ASSERT(sizeof(struct rx_frame_record) == 240u,
	     "rx_frame_record layout changed");
BUILD_ASSERT(sizeof(struct fpga_record_header) == 40u,
	     "fpga_record_header layout changed");
BUILD_ASSERT(sizeof(struct fpga_record) == 248u,
	     "fpga_record layout changed");

#endif /* RF_LINK_FUTURE_H_ */
```

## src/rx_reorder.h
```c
#ifndef RF_LINK_RX_REORDER_H_
#define RF_LINK_RX_REORDER_H_

#include <stdint.h>

#include "rf_link_proto.h"
#include "rf_link_future.h"

struct rx_reorder_stats {
	uint32_t frames;
	uint32_t samples;
	uint32_t bytes;
	uint32_t lost_frames;
	uint32_t lost_samples;
	uint32_t duplicates;
	uint32_t late_frames;
	uint32_t index_estimated;
	uint32_t bad_magic;
	uint32_t bad_size;
	uint32_t bad_sample_count;
	uint32_t extended_frame_seq;
	uint16_t last_seq;
	int16_t last_first_sample;
	int16_t last_last_sample;
	struct rx_missing_range last_missing;
};

void rx_reorder_init(void);
int rx_reorder_process_frame(const struct rf_frame *frame, uint8_t len);
int rx_reorder_process_packet(const struct rf_frame *frame, uint16_t len,
			      uint64_t rx_tick,
			      struct rx_frame_record *record);
void rx_reorder_stats_get(struct rx_reorder_stats *stats);

#endif /* RF_LINK_RX_REORDER_H_ */
```
